# nrf7140_application register map
Vendor: Nordic Semiconductor; Series: nRF71; File version: 1
CPU: CM33 r0p4, little endian, MPU, FPU, 3 interrupt priority bits, 480 interrupts, 8 SAU regions
Registers are 32-bit, read-write, reset 0x0 unless marked. A register's access mark holds for its fields unless they carry their own. Offsets are from the block's base; [hi:lo] are bit positions; lines under a group give offsets from that group; {n}, {i} and the like mark numbered series; 'fields as' and 'values as' point back to an identical list.

## GLOBAL_FICR_NS — Factory Information Configuration Registers
Base 0x0FFFE000
0x00 SOCINFO group — Unspecified
  0x00 PARTNO ro reset 0xFFFFFFFF — Part number.
    [31:0] PART
  0x04 HWREVISION ro reset 0xFFFFFFFF — Hardware revision.
    [31:0] HWREVISION — Hardvare revision.
  0x08 PRODUCTIONREVISION ro reset 0xFFFFFFFF — Production reversion.
0x0C BLE group — Unspecified
  0x00 ADDRTYPE ro reset 0xFFFFFFFF — Device address type.
    [0] TYPE
      0=Public address; 1=Random address
  {0x4+4j} ADDR[{j}] (j=0..1) ro reset 0xFFFFFFFF — Description collection: 48 bit device address.
    [31:0] ADDR — Device address [n].
  {0xC+4j} ER[{j}] (j=0..3) ro reset 0xFFFFFFFF — Description collection: Encryption Root.
    [31:0] ER — Encryption root word [n].
  {0x1C+4j} IR[{j}] (j=0..3) ro reset 0xFFFFFFFF — Description collection: Identity Root.
    [31:0] IR — Identity root word [n].
0x40 NFC group — Unspecified
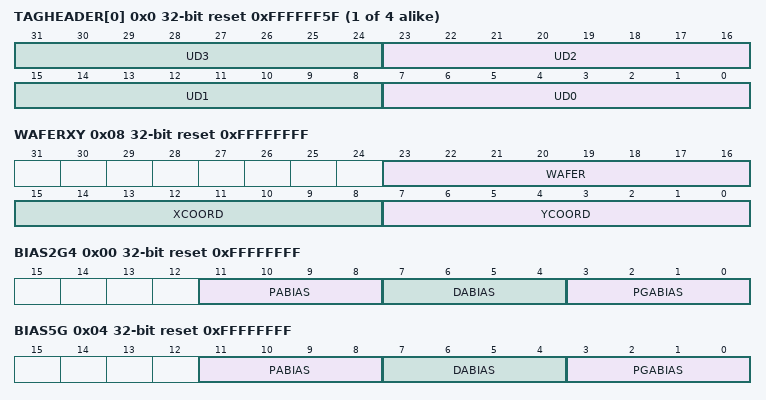
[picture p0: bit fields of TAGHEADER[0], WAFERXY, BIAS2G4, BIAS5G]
  {0x0+4j} TAGHEADER[{j}] (j=0..3) ro reset 0xFFFFFF5F — Description collection: Default header for NFC Tag.
    [8n+7:8n] UD{n} (n=0..3) — Unique identifier byte {n}
0x50 INFO group — Device info
  0x00 CONFIGID ro reset 0xFFFFFFFF — Configuration identifier
    [15:0] HWID — Identification number for the HW
  0x04 PART ro reset 0xFFFFFFFF — Part code
    [31:0] PART
      0xFFFFFFFF=Unspecified
  0x08 VARIANT ro reset 0xFFFFFFFF — Part Variant, Hardware version and Production configuration
    [31:0] VARIANT — Part Variant, Hardware version and Production configuration, encoded as ASCII
      0xFFFFFFFF=Unspecified
  0x0C PACKAGE ro reset 0xFFFFFFFF — Package option
    [31:0] PACKAGE
      0xFFFFFFFF=Unspecified
  0x10 RAM ro reset 0xFFFFFFFF — RAM variant
    [31:0] RAM
      0xFFFFFFFF=Unspecified
  0x14 MRAM ro reset 0xFFFFFFFF — MRAM variant
    [31:0] MRAM
      0xFFFFFFFF=Unspecified
  0x18 CODEPAGESIZE ro reset 0x1000 — Code memory page size in bytes
    [31:0] CODEPAGESIZE
      0xFFFFFFFF=Unspecified
  0x1C CODESIZE ro reset 0x100 — Code memory size
    [31:0] CODESIZE — Code memory size in number of pages
      0xFFFFFFFF=Unspecified
  0x20 DEVICETYPE ro
    [31:0] DEVICETYPE
      0=Die (Device is an physical DIE); 0xFFFFFFFF=FPGA (Device is an FPGA)
0x80 WIFI group — Unspecified
  0x00 DISABLE5GHZ ro reset 0xFFFFFFFF
    [31:0] VALUE — Disable 5GHz support. Firmware reads at start of day. Set to 0x50FA50FA to disable 5GHz operation.
  {0x4+4j} MACADDR0[{j}] (j=0..2) ro reset 0xFFFFFFFF — Description collection: Least significant 4 bytes of default MAC address for VIF[n].
    [31:0] MACADDRLO — MAC address for VIF[n] bytes 3:0.
  {0x10+4j} MACADDR1[{j}] (j=0..2) ro reset 0xFFFFFFFF — Description collection: Most significant 2 bytes of default MAC address for VIF[n].
    [15:0] MACADDRHI — MAC address for VIF[n] bytes 5:4.
0xC0 PRODTEST group — Unspecified
  0x00 CP group — Unspecified
    {0x0+4k} LOTNR[{k}] (k=0..1) ro reset 0xFFFFFFFF — Description collection: Lot number.
      [31:0] LOTNR — Lot number
    0x08 WAFERXY ro reset 0xFFFFFFFF — Wafer number and die X,Y coordinate.
      [23:16] WAFER — Wafer number
      [15:8] XCOORD — Die x coordinate
      [7:0] YCOORD — Die y coordinate
    0x0C PROGVERSION1 ro reset 0xFFFFFFFF — CP1 test program version.
      [31:0] VAL — CP1 test program version
    0x10 PROGVERSION2 ro reset 0xFFFFFFFF — CP2 test program version.
      [31:0] VAL — CP2 test program version
    0x14 PASSID1 ro reset 0xFFFFFFFF — CP1 pass ID.
      [31:0] VAL
    0x18 PASSID2 ro reset 0xFFFFFFFF — CP2 pass ID.
      [31:0] VAL
    0x1C TIMESTAMP1 ro reset 0xFFFFFFFF — Timestamp for when CP1 starts or ends (YYYYMMDDTHHMMSS)
      [31:0] VAL — CP1 timestamp
    0x20 TIMESTAMP2 ro reset 0xFFFFFFFF — Timestamp for when CP2 starts or ends (YYYYMMDDTHHMMSS)
      [31:0] VAL — CP2 timestamp
  0x24 FT group — Unspecified
    0x00 PROGVERSION1 ro reset 0xFFFFFFFF — FT1 test program version.
      [31:0] PROGVERSION1 — FT1 test program version
    0x04 PROGVERSION2 ro reset 0xFFFFFFFF — FT2/EQA test program version.
      [31:0] PROGVERSION2 — FT2/EQA test program version
    0x08 PASSID1 ro reset 0xFFFFFFFF — FT1 pass ID.
      [31:0] VAL
    0x0C PASSID2 ro reset 0xFFFFFFFF — FT2/EQA pass ID.
      [31:0] VAL
    0x10 TIMESTAMP1 ro reset 0xFFFFFFFF — Timestamp for when FT1 starts or ends (YYYYMMDDTHHMMSS)
      [31:0] VAL — FT1 timestamp
    0x14 TIMESTAMP2 ro reset 0xFFFFFFFF — Timestamp for when FT2/EQA starts or ends (YYYYMMDDTHHMMSS)
      [31:0] VAL — FT2/EQA timestamp
0x100 TRIM group — Unspecified
  0x00 SYSCTRL group — Unspecified
    0x00 FLL16M group — Unspecified
      0x00 CONFIG group — Unspecified
        0x00 CFGCKSW16M ro reset 0xFFFFFFFF — Config value for SYSCTRL.FLL16M.CONFIG.CFGCKSW16M
          [31:0] VALUE — Config value
      0x04 TRIM group — Unspecified
        0x00 RCOARSE ro reset 0xFFFFFFFF — Trim value for SYSCTRL.FLL16M.TRIM.RCOARSE
          [31:0] VALUE — Trim value
        0x04 RFINE ro reset 0xFFFFFFFF — Trim value for SYSCTRL.FLL16M.TRIM.RFINE
          [31:0] VALUE — Trim value
        0x08 VSUP ro reset 0xFFFFFFFF — Trim value for SYSCTRL.FLL16M.TRIM.VSUP
          [31:0] VALUE — Trim value
        0x0C CKSW16MTRIM ro reset 0xFFFFFFFF — Trim value for SYSCTRL.FLL16M.TRIM.CKSW16MTRIM
          [31:0] VALUE — Trim value
        0x10 TCOEF ro reset 0xFFFFFFFF — Trim value for SYSCTRL.FLL16M.TRIM.TCOEF
          [31:0] VALUE — Trim value
    0x18 LFRC group — Unspecified
      0x00 CAL group — Unspecified
        0x00 LFRCOSCTRIM ro reset 0xFFFFFFFF — Trim value for SYSCTRL.LFRC.CAL.LFRCOSCTRIM
          [31:0] VALUE — Trim value
    0x1C LFXO group — Unspecified
      0x00 TRIM group — Unspecified
        0x00 PDLOWERTHR ro reset 0xFFFFFFFF — Trim value for SYSCTRL.LFXO.TRIM.PDLOWERTHR
          [31:0] VALUE — Trim value
        0x04 PDUPPERTHR ro reset 0xFFFFFFFF — Trim value for SYSCTRL.LFXO.TRIM.PDUPPERTHR
          [31:0] VALUE — Trim value
        0x08 BIAS ro reset 0xFFFFFFFF — Trim value for SYSCTRL.LFXO.TRIM.BIAS
          [31:0] VALUE — Trim value
        0x0C PIXO ro reset 0xFFFFFFFF — Trim value for SYSCTRL.LFXO.TRIM.PIXO
          [31:0] VALUE — Trim value
        0x10 TRIMBUS ro reset 0xFFFFFFFF — Trim value for SYSCTRL.LFXO.TRIM.TRIMBUS
          [31:0] VALUE — Trim value
    0x30 HFXO64M group — Unspecified
      0x00 TRIM group — Unspecified
        0x00 DOUBLERCOMP ro reset 0xFFFFFFFF — Trim value for SYSCTRL.HFXO64M.TRIM.DOUBLERCOMP
          [31:0] VALUE — Trim value
        0x04 CHIRPTUNE ro reset 0xFFFFFFFF — Trim value for SYSCTRL.HFXO64M.TRIM.CHIRPTUNE
          [31:0] VALUE — Trim value
        0x08 RTUNE ro reset 0xFFFFFFFF — Trim value for SYSCTRL.HFXO64M.TRIM.RTUNE
          [31:0] VALUE — Trim value
    0x3C LFLPRC group — Unspecified
      0x00 VSUP ro reset 0xFFFFFFFF — Trim value for SYSCTRL.LFLPRC.TRIM.VSUP
        [31:0] VALUE — Trim value
      0x04 RCOARSE ro reset 0xFFFFFFFF — Trim value for SYSCTRL.LFLPRC.TRIM.RCOARSE
        [31:0] VALUE — Trim value
      0x08 RFINE ro reset 0xFFFFFFFF — Trim value for SYSCTRL.LFLPRC.TRIM.RFINE
        [31:0] VALUE — Trim value
      0x0C PWMFINE ro reset 0xFFFFFFFF — Trim value for SYSCTRL.LFLPRC.TRIM.PWMFINE
        [31:0] VALUE — Trim value
    0x4C VDETPOF5V0 group — Unspecified
      0x00 TRIM group — Unspecified
        0x00 POFWARN ro reset 0xFFFFFFFF — Trim value for SYSCTRL.VDETPOF5V0.TRIM.POFWARN
          [31:0] VALUE — Trim value
    0x50 VDETPOFVBAT group — Unspecified
      0x00 TRIM group — Unspecified
        0x00 POFWARN ro reset 0xFFFFFFFF — Trim value for SYSCTRL.VDETPOFVBAT.TRIM.POFWARN
          [31:0] VALUE — Trim value
    0x80 MBIAS group — Unspecified
      0x00 CONFIG group — Unspecified
        0x00 CFG ro reset 0xFFFFFFFF — Config value for SYSCTRL.MBIAS.CONFIG.CFG
          [31:0] VALUE — Trim value
      0x04 TRIM group — Unspecified
        0x00 MBIASIBPP ro reset 0xFFFFFFFF — Trim value for SYSCTRL.MBIAS.TRIM.MBIASIBPP
          [31:0] VALUE — Trim value
        0x04 MBIASIBPSR ro reset 0xFFFFFFFF — Trim value for SYSCTRL.MBIAS.TRIM.MBIASIBPSR
          [31:0] VALUE — Trim value
    0x8C OSCRFR group — Unspecified
      0x00 TRIM group — Unspecified
        0x00 OSC ro reset 0xFFFFFFFF — Trim value for SYSCTRL.OSCRFR.TRIM.OSC
          [31:0] VALUE — Trim value
        0x04 IBPSR ro reset 0xFFFFFFFF — Trim value for SYSCTRL.OSCRFR.TRIM.IBPSR
          [31:0] VALUE — Trim value
    0x94 VREG1V0 group — Unspecified
      0x00 TRIM group — Unspecified
        0x00 IREF ro reset 0xFFFFFFFF — Trim value for SYSCTRL.VREG1V0.TRIM.IREF
          [31:0] VALUE — Trim value
        0x04 HIGHPOWER ro reset 0xFFFFFFFF — Trim value for SYSCTRL.VREG1V0.TRIM.HIGHPOWER
          [31:0] VALUE — Trim value
        0x08 LOWPOWER ro reset 0xFFFFFFFF — Trim value for SYSCTRL.VREG1V0.TRIM.LOWPOWER
          [31:0] VALUE — Trim value
        0x0C ULPR ro reset 0xFFFFFFFF — Trim value for SYSCTRL.VREG1V0.TRIM.ULPR
          [31:0] VALUE — Trim value
      0x10 VOUTHPNOMINAL ro reset 0xFFFFFFFF — Config value for SYSCTRL.VREG1V0.VOUTHPNOMINAL
        [31:0] VALUE — Config value
    0xA8 VREGAO0V8 group — Unspecified
      0x00 TRIM group — Unspecified
        0x00 IREF ro reset 0xFFFFFFFF — Trim value for SYSCTRL.VREGAO0V8.TRIM.IREF
          [31:0] VALUE — Trim value
        0x04 HIGHPOWER ro reset 0xFFFFFFFF — Trim value for SYSCTRL.VREGAO0V8.TRIM.HIGHPOWER
          [31:0] VALUE — Trim value
        0x08 LOWPOWER ro reset 0xFFFFFFFF — Trim value for SYSCTRL.VREGAO0V8.TRIM.LOWPOWER
          [31:0] VALUE — Trim value
        0x0C ULTRALOWPOWER ro reset 0xFFFFFFFF — Trim value for SYSCTRL.VREGAO0V8.TRIM.ULTRALOWPOWER
          [31:0] VALUE — Trim value
        0x10 BPDET ro reset 0xFFFFFFFF — Trim value for SYSCTRL.VREGAO0V8.TRIM.BPDET
          [31:0] VALUE — Trim value
    0xBC VREGAO1V8 group — Unspecified
      0x00 TRIM group — Unspecified
        0x00 IREF ro reset 0xFFFFFFFF — Trim value for SYSCTRL.VREGAO1V8.TRIM.IREF
          [31:0] VALUE — Trim value
        0x04 VREF ro reset 0xFFFFFFFF — Trim value for SYSCTRL.VREGAO1V8.TRIM.VREF
          [31:0] VALUE — Trim value
        0x08 LOWPOWER ro reset 0xFFFFFFFF — Trim value for SYSCTRL.VREGAO1V8.TRIM.LOWPOWER
          [31:0] VALUE — Trim value
        0x0C LOWPOWERDIFF ro reset 0xFFFFFFFF — Trim value for SYSCTRL.VREGAO1V8.TRIM.LOWPOWERDIFF
          [31:0] VALUE — Trim value
    0xCC VREGMAIN group — Unspecified
      0x00 TRIM group — Unspecified
        0x00 BIASIBPP ro reset 0xFFFFFFFF — Trim value for SYSCTRL.VREGMAIN.TRIM.BIASIBPP
          [31:0] VALUE — Trim value
        0x04 BIASIBPSR ro reset 0xFFFFFFFF — Trim value for SYSCTRL.VREGMAIN.TRIM.BIASIBPSR
          [31:0] VALUE — Trim value
        0x08 VDDAO1V8HYSTOUTPUT ro reset 0xFFFFFFFF — Trim value for SYSCTRL.VREGMAIN.TRIM.VDDAO1V8HYSTOUTPUT
          [31:0] VALUE — Trim value
        0x0C VDDAO1V8PWMOUTPUT ro reset 0xFFFFFFFF — Trim value for SYSCTRL.VREGMAIN.TRIM.VDDAO1V8PWMOUTPUT
          [31:0] VALUE — Trim value
        0x10 VDD1V0HYSTOUTPUT ro reset 0xFFFFFFFF — Trim value for SYSCTRL.VREGMAIN.TRIM.VDD1V0HYSTOUTPUT
          [31:0] VALUE — Trim value
        0x14 VDDVS0V8HYSTOUTPUT ro reset 0xFFFFFFFF — Trim value for SYSCTRL.VREGMAIN.TRIM.VDDVS0V8HYSTOUTPUT
          [31:0] VALUE — Trim value
        0x18 VDDVS0V8PWMOUTPUT ro reset 0xFFFFFFFF — Trim value for SYSCTRL.VREGMAIN.TRIM.VDDVS0V8PWMOUTPUT
          [31:0] VALUE — Trim value
        0x1C VDD1V0PWMOUTPUT ro reset 0xFFFFFFFF — Trim value for SYSCTRL.VREGMAIN.TRIM.VDD1V0PWMOUTPUT
          [31:0] VALUE — Trim value
        0x20 ZCROSS ro reset 0xFFFFFFFF — Trim value for SYSCTRL.VREGMAIN.TRIM.ZCROSS
          [31:0] VALUE — Trim value
        0x24 HSILIM ro reset 0xFFFFFFFF — Trim value for SYSCTRL.VREGMAIN.TRIM.HSILIM
          [31:0] VALUE — Trim value
        0x28 ICMP ro reset 0xFFFFFFFF — Trim value for SYSCTRL.VREGMAIN.TRIM.ICMP
          [31:0] VALUE — Trim value
        0x2C VGND ro reset 0xFFFFFFFF — Trim value for SYSCTRL.VREGMAIN.TRIM.VGND
          [31:0] VALUE — Trim value
      0x30 CONFIG group — Unspecified
        0x00 CFGCH1 ro reset 0xFFFFFFFF — Config value for SYSCTRL.VREGMAIN.CONFIG.CFGCH1
          [31:0] VALUE — Config value
      0x34 MODE ro reset 0xFFFFFFFF — Config value for SYSCTRL.VREGMAIN.MODE
        [31:0] VALUE — Config value
    0x104 VREGMRAM130 group — Unspecified
      0x00 TRIM group — Unspecified
        0x00 VBG ro reset 0xFFFFFFFF — Trim value for SYSCTRL.VREGMRAM130.TRIM.VBG
          [31:0] VALUE — Trim value
        0x04 BIAS ro reset 0xFFFFFFFF — Trim value for SYSCTRL.VREGMRAM130.TRIM.BIAS
          [31:0] VALUE — Trim value
        0x08 VPR ro reset 0xFFFFFFFF — Trim value for SYSCTRL.VREGMRAM130.TRIM.VPR
          [31:0] VALUE — Trim value
        0x0C VREF ro reset 0xFFFFFFFF — Trim value for SYSCTRL.VREGMRAM130.TRIM.VREF
          [31:0] VALUE — Trim value
    0x114 VREGMRAM131 group — Unspecified
      0x00 TRIM group — Unspecified
        0x00 VBG ro reset 0xFFFFFFFF — Trim value for SYSCTRL.VREGMRAM131.TRIM.VBG
          [31:0] VALUE — Trim value
        0x04 BIAS ro reset 0xFFFFFFFF — Trim value for SYSCTRL.VREGMRAM131.TRIM.BIAS
          [31:0] VALUE — Trim value
        0x08 VPR ro reset 0xFFFFFFFF — Trim value for SYSCTRL.VREGMRAM131.TRIM.VPR
          [31:0] VALUE — Trim value
        0x0C VREF ro reset 0xFFFFFFFF — Trim value for SYSCTRL.VREGMRAM131.TRIM.VREF
          [31:0] VALUE — Trim value
    0x124 VREGVS0V8 group — Unspecified
      0x00 TRIM group — Unspecified
        0x00 IREF ro reset 0xFFFFFFFF — Trim value for SYSCTRL.VREGVS0V8.TRIM.IREF
          [31:0] VALUE — Trim value
        0x04 HIGHPOWER ro reset 0xFFFFFFFF — Trim value for SYSCTRL.VREGVS0V8.TRIM.HIGHPOWER
          [31:0] VALUE — Trim value
        0x08 LOWPOWER ro reset 0xFFFFFFFF — Trim value for SYSCTRL.VREGVS0V8.TRIM.LOWPOWER
          [31:0] VALUE — Trim value
        0x0C ULPR ro reset 0xFFFFFFFF — Trim value for SYSCTRL.VREGVS0V8.TRIM.ULPR
          [31:0] VALUE — Trim value
    0x134 VREGUSB group — Unspecified
      0x00 TRIM group — Unspecified
        0x00 TRIMVDD ro reset 0xFFFFFFFF — Trim value for SYSCTRL.VREGUSB.TRIM.TRIMVDD
          [31:0] VALUE — Trim value
        0x04 TRIMIBP ro reset 0xFFFFFFFF — Trim value for SYSCTRL.VREGUSB.TRIM.TRIMIBP
          [31:0] VALUE — Trim value
        0x08 TRIM0V8 ro reset 0xFFFFFFFF — Trim value for SYSCTRL.VREGUSB.TRIM.TRIM0V8
          [31:0] VALUE — Trim value
        0x0C TRIM3V3 ro reset 0xFFFFFFFF — Trim value for SYSCTRL.VREGUSB.TRIM.TRIM3V3
          [31:0] VALUE — Trim value
    0x144 VDETAO0V8 group — Unspecified
      0x00 TRIM group — Unspecified
        0x00 BROWNOUT ro reset 0xFFFFFFFF — Trim value for SYSCTRL.VDETAO0V8.TRIM.BROWNOUT
          [31:0] VALUE — Trim value
        0x04 PWRGOOD ro reset 0xFFFFFFFF — Trim value for SYSCTRL.VDETAO0V8.TRIM.PWRGOOD
          [31:0] VALUE — Trim value
      0x08 CONFIG group — Unspecified
        0x00 BROWNOUTHP ro reset 0xFFFFFFFF — Config value for SYSCTRL.VDETAO0V8.CONFIG.BROWNOUTHP
          [31:0] VALUE — Config value
    0x150 VDETAO1V8 group — Unspecified
      0x00 TRIM group — Unspecified
        0x00 BROWNOUTLVLHIGH ro reset 0xFFFFFFFF — Trim value for SYSCTRL.VDETAO1V8.TRIM.BROWNOUTLVLHIGH
          [31:0] VALUE — Trim value
        0x04 BROWNOUTLVLLOW ro reset 0xFFFFFFFF — Trim value for SYSCTRL.VDETAO1V8.TRIM.BROWNOUTLVLLOW
          [31:0] VALUE — Trim value
    0x158 VDETVS0V8 group — Unspecified
      0x00 TRIM group — Unspecified
        0x00 BROWNOUT ro reset 0xFFFFFFFF — Trim value for SYSCTRL.VDETVS0V8.TRIM.BROWNOUT
          [31:0] VALUE — Trim value
        0x04 PWRGOOD ro reset 0xFFFFFFFF — Trim value for SYSCTRL.VDETVS0V8.TRIM.PWRGOOD
          [31:0] VALUE — Trim value
    0x160 VDETAO5V0 group — Unspecified
      0x00 TRIM group — Unspecified
        0x00 PWRGOOD ro reset 0xFFFFFFFF — Trim value for SYSCTRL.VDETAO5V0.TRIM.PWRGOOD
          [31:0] VALUE — Trim value
    0x164 VDET1V0 group — Unspecified
      0x00 TRIM group — Unspecified
        0x00 PWRGOOD ro reset 0xFFFFFFFF — Trim value for SYSCTRL.VDET1V0.TRIM.PWRGOOD
          [31:0] VALUE — Trim value
    0x168 HSFLL120 group — Unspecified
      0x00 TRIM group — Unspecified
        0x00 VSUP ro reset 0xFFFFFFFF — Trim value for SYSCTRL.HSFLL120.TRIM.VSUP
          [31:0] VALUE — Trim value
        {0x4+4m} COARSE[{m}] (m=0..5) ro reset 0xFFFFFFFF — Description collection: Trim value for SYSCTRL.HSFLL120.TRIM.COARSE
          [31:0] VALUE — Trim value
        {0x1C+4m} FINE[{m}] (m=0..5) ro reset 0xFFFFFFFF — Description collection: Trim value for SYSCTRL.HSFLL120.TRIM.FINE
          [31:0] VALUE — Trim value
        0x34 TCOEF ro reset 0xFFFFFFFF — Trim value for SYSCTRL.HSFLL120.TRIM.TCOEF
          [31:0] VALUE — Trim value
    0x1A0 HSFLL121 group — Unspecified
      0x00 TRIM group — Unspecified
        0x00 VSUP ro reset 0xFFFFFFFF — Trim value for SYSCTRL.HSFLL121.TRIM.VSUP
          [31:0] VALUE — Trim value
        {0x4+4m} COARSE[{m}] (m=0..5) ro reset 0xFFFFFFFF — Description collection: Trim value for SYSCTRL.HSFLL121.TRIM.COARSE
          [31:0] VALUE — Trim value
        {0x1C+4m} FINE[{m}] (m=0..5) ro reset 0xFFFFFFFF — Description collection: Trim value for SYSCTRL.HSFLL121.TRIM.FINE
          [31:0] VALUE — Trim value
        0x34 TCOEF ro reset 0xFFFFFFFF — Trim value for SYSCTRL.HSFLL121.TRIM.TCOEF
          [31:0] VALUE — Trim value
    0x1D8 HSFLL122 group — Unspecified
      0x00 TRIM group — Unspecified
        0x00 VSUP ro reset 0xFFFFFFFF — Trim value for SYSCTRL.HSFLL122.TRIM.VSUP
          [31:0] VALUE — Trim value
        {0x4+4m} COARSE[{m}] (m=0..5) ro reset 0xFFFFFFFF — Description collection: Trim value for SYSCTRL.HSFLL122.TRIM.COARSE
          [31:0] VALUE — Trim value
        {0x1C+4m} FINE[{m}] (m=0..5) ro reset 0xFFFFFFFF — Description collection: Trim value for SYSCTRL.HSFLL122.TRIM.FINE
          [31:0] VALUE — Trim value
        0x34 TCOEF ro reset 0xFFFFFFFF — Trim value for SYSCTRL.HSFLL122.TRIM.TCOEF
          [31:0] VALUE — Trim value
    0x210 MEMCONF120 group — Unspecified
      {0x0+4l} REPAIR[{l}] (l=0..18) group — Unspecified
        0x00 BITLINE ro reset 0xFFFFFFFF — Description cluster: Trim value for SYSCTRL.MEMCONF120.REPAIR[n].BITLINE
          [31:0] VALUE — Trim value
      {0x4C+4l} BLOCKTYPE[{l}] (l=0..7) group — Unspecified
        0x00 TRIM ro reset 0xFFFFFFFF — Description cluster: Trim value for SYSCTRL.MEMCONF120.BLOCKTYPE[n].TRIM
          [31:0] VALUE — Trim value
    0x27C MEMCONF130 group — Unspecified
      {0x0+4l} BLOCKTYPE[{l}] (l=0..2) group — Unspecified
        0x00 TRIM ro reset 0xFFFFFFFF — Description cluster: Trim value for SYSCTRL.MEMCONF130.BLOCKTYPE[n].TRIM
          [31:0] VALUE — Trim value
  0x288 GLOBAL group — Unspecified
    0x00 SAADC group — Unspecified
      {0x0+4l} CAL[{l}] (l=0..2) ro reset 0xFFFFFFFF — Description collection: Trim value for GLOBAL.SAADC.CAL
        [31:0] VALUE — Trim value
      0x0C CALREF ro reset 0xFFFFFFFF — Trim value for GLOBAL.SAADC.CALREF
        [31:0] VALUE — Trim value
      {0x10+4l} LINCALCOEFF[{l}] (l=0..5) ro reset 0xFFFFFFFF — Description collection: Trim value for GLOBAL.SAADC.TRIM.LINCALCOEFF
        [31:0] VALUE — Trim value
    0x28 TEMP group — Unspecified
      0x00 CALIB ro reset 0xFFFFFFFF — Trim value for GLOBAL.TEMP.CALIB
        [31:0] VALUE — Trim value
    0x2C NFCT group — Unspecified
      0x00 BIASCFG ro reset 0xFFFFFFFF — Trim value for NFCT.BIASCFG
        [31:0] VALUE — Trim value
    0x30 CANPLL group — Unspecified
      0x00 TRIM group — Unspecified
        0x00 CTUNE ro reset 0xFFFFFFFF — Trim value for GLOBAL.CANPLL.TRIM.CTUNE
          [31:0] VALUE — Trim value
    0x34 CANPLLPM group — Unspecified
      0x00 TRIM group — Unspecified
        0x00 VREFPM ro reset 0xFFFFFFFF — Trim value for GLOBAL.CANPLLPM.TRIM.VREFPM
          [31:0] VALUE — Trim value
    0x38 COMP group — Unspecified
      0x00 REFTRIM ro reset 0xFFFFFFFF — Trim value for GLOBAL.COMP.REFTRIM
        [31:0] VALUE — Trim value
      0x04 RCALTRIM ro reset 0xFFFFFFFF — Trim value for GLOBAL.COMP.DFT.RCALTRIM
        [31:0] VALUE — Trim value
  0x2C8 APPLICATION group — Unspecified
    0x00 HSFLL group — Unspecified
      0x00 TRIM group — Unspecified
        0x00 VSUP ro reset 0xFFFFFFFF — Trim value for APPLICATION.HSFLL.TRIM.VSUP
          [31:0] VALUE — Trim value
        {0x4+4m} COARSE[{m}] (m=0..5) ro reset 0xFFFFFFFF — Description collection: Trim value for APPLICATION.HSFLL.TRIM.COARSE
          [31:0] VALUE — Trim value
        {0x1C+4m} FINE[{m}] (m=0..5) ro reset 0xFFFFFFFF — Description collection: Trim value for APPLICATION.HSFLL.TRIM.FINE
          [31:0] VALUE — Trim value
        0x34 TCOEF ro reset 0xFFFFFFFF — Trim value for APPLICATION.HSFLL.TRIM.TCOEF
          [31:0] VALUE — Trim value
    0x38 MEMCONF group — Unspecified
      {0x0+4l} BLOCKTYPE[{l}] (l=0..3) group — Unspecified
        0x00 TRIM ro reset 0xFFFFFFFF — Description cluster: Trim value for APPLICATION.MEMCONF.BLOCKTYPE[n].TRIM
          [31:0] VALUE — Trim value
  0x310 RADIOCORE group — Unspecified
    0x00 HSFLL group — Unspecified
      0x00 TRIM group — Unspecified
        0x00 VSUP ro reset 0xFFFFFFFF — Trim value for RADIOCORE.HSFLL.TRIM.VSUP
          [31:0] VALUE — Trim value
        {0x4+4m} COARSE[{m}] (m=0..5) ro reset 0xFFFFFFFF — Description collection: Trim value for RADIOCORE.HSFLL.TRIM.COARSE
          [31:0] VALUE — Trim value
        {0x1C+4m} FINE[{m}] (m=0..5) ro reset 0xFFFFFFFF — Description collection: Trim value for RADIOCORE.HSFLL.TRIM.FINE
          [31:0] VALUE — Trim value
        0x34 TCOEF ro reset 0xFFFFFFFF — Trim value for RADIOCORE.HSFLL.TRIM.TCOEF
          [31:0] VALUE — Trim value
    0x38 MEMCONF group — Unspecified
      {0x0+4l} BLOCKTYPE[{l}] (l=0..3) group — Unspecified
        0x00 TRIM ro reset 0xFFFFFFFF — Description cluster: Trim value for RADIOCORE.MEMCONF.BLOCKTYPE[n].TRIM
          [31:0] VALUE — Trim value
    0x48 RADIO group — Unspecified
      0x00 SPHYNXANA group — Unspecified
        {0x0+4m} FSCTRL{m} ro reset 0xFFFFFFFF (m=0..2) — Trim value for RADIOCORE.RADIO.SPHYNXANA.FSCTRL{m}
          [31:0] VALUE — Trim value
        0x0C RXCTRL ro reset 0xFFFFFFFF — Trim value for RADIOCORE.RADIO.SPHYNXANA.RXCTRL
          [31:0] VALUE — Trim value
        0x10 OVRRXTRIMCODE ro reset 0xFFFFFFFF — Trim value for RADIOCORE.RADIO.SPHYNXANA.OVRRXTRIMCODE
          [31:0] VALUE — Trim value
      0x14 RXAGC group — Unspecified
        0x00 CALIBRATION ro reset 0xFFFFFFFF — RADIOCORE.RADIO.RXAGC.CALIBRATION
          [31:0] VALUE — Trim value
      0x18 PVTTOT ro reset 0xFFFFFFFF — Trim value for RADIOCORE.RADIO.PVTTOT
        [31:0] VALUE — Trim value
      0x1C KDTC ro reset 0xFFFFFFFF — Trim value for RADIOCORE.RADIO.KDTC
        [31:0] VALUE — Trim value
      0x20 TXHFGAIN ro reset 0xFFFFFFFF — Trim value for RADIOCORE.RADIO.TXHFGAIN
        [31:0] VALUE — Trim value
      0x24 PVTTOFIX ro reset 0xFFFFFFFF — Trim value for RADIOCORE.RADIO.PVTTOFIX
        [31:0] VALUE — Trim value
      0x28 LOOPGAIN ro reset 0xFFFFFFFF — Trim value for RADIOCORE.RADIO.ADPLLTRIMCOMMAND0
        [31:0] VALUE — Trim value
  0x384 VREG1V80V8 group — Unspecified
    0x00 TRIM group — Unspecified
      0x00 IREF ro reset 0xFFFFFFFF — Trim value for SYSCTRL.VREGVS0V8.TRIM.IREF
        [31:0] VALUE — Trim value
      0x04 HIGHPOWER ro reset 0xFFFFFFFF — Trim value for SYSCTRL.VREGVS0V8.TRIM.HIGHPOWER
        [31:0] VALUE — Trim value
      0x08 LOWPOWER ro reset 0xFFFFFFFF — Trim value for SYSCTRL.VREGVS0V8.TRIM.LOWPOWER
        [31:0] VALUE — Trim value
      0x0C ULPR ro reset 0xFFFFFFFF — Trim value for SYSCTRL.VREGVS0V8.TRIM.ULPR
        [31:0] VALUE — Trim value
  0x394 AUDIOPLL group — Unspecified
    0x00 TRIM group — Unspecified
      0x00 CTUNE ro reset 0xFFFFFFFF — Trim value for SYSCTRL.AUDIOPLL.TRIM.CTUNE
        [31:0] VALUE — Trim value
  0x398 AUDIOPLLPM group — Unspecified
    0x00 TRIM group — Unspecified
      0x00 VREFPM ro reset 0xFFFFFFFF — Trim value for SYSCTRL.AUDIOPLLPM.TRIM.VREFPM
        [31:0] VALUE — Trim value
  0x39C USBHSPLL group — Unspecified
    0x00 TRIM group — Unspecified
      0x00 CTUNE ro reset 0xFFFFFFFF — Trim value for SYSCTRL.USBHSPLL.TRIM.CTUNE
        [31:0] VALUE — Trim value
  0x3CC BOOT group — Unspecified
    0x00 GPIO group — Unspecified
      0x00 PORTCNF group — Unspecified
        0x00 DRIVECTRL group — Unspecified
          {0x0+4p} P[{p}] (p=0..1) ro reset 0xFFFFFFFF — Description collection: Trim value for GPIO.Pn.PORTCNF.DRIVECTRL
            [31:0] VALUE — Trim value
    0x08 VREG1V0 group — Unspecified
      0x00 VOUTHPRADIOHELPER ro reset 0xFFFFFFFF — Config value for SYSCTRL.VREG1V0.VOUTHPRADIO when VREG1V0 used in Helper mode
        [31:0] VALUE — Config value
      0x04 VOUTHPNOMINAL ro reset 0xFFFFFFFF — Config value for SYSCTRL.VREG1V0.VOUTHPNOMINAL
        [31:0] VALUE — Config value
    0x10 HSFLL120 group — Unspecified
      0x00 TRIM group — Unspecified
        0x00 VSUP ro reset 0xFFFFFFFF — Trim value for SYSCTRL.HSFLL120.TRIM.VSUP
          [31:0] VALUE — Trim value
        0x04 COARSE ro reset 0xFFFFFFFF — Trim value for SYSCTRL.HSFLL120.TRIM.COARSE
          [31:0] VALUE — Trim value
        0x08 FINE ro reset 0xFFFFFFFF — Trim value for SYSCTRL.HSFLL120.TRIM.FINE
          [31:0] VALUE — Trim value
        0x0C TCOEF ro reset 0xFFFFFFFF — Trim value for SYSCTRL.HSFLL120.TRIM.TCOEF
          [31:0] VALUE — Trim value
    0x20 OTPC group — Unspecified
      0x00 WAITSTATES ro reset 0xFFFFFFFF — Config value for GLOBAL.OTPC.WAITSTATES
      0x04 FREQUENCY ro reset 0xFFFFFFFF — Config value for GLOBAL.OTPC.FREQUENCY
        [31:0] FREQUENCY — Frequency in MHz
  0x3F4 COMMON group — Unspecified
    0x00 FFFF ro reset 0xFFFFFFFF — Value to be written to multibit MIRROR register in MMIs (MIRROR=1)
      [31:0] FFFF — Mirror register value
    0x04 ZERO ro reset 0xFFFFFFFF — Value to be written to MIRROR register in MMIs (MIRROR=0)
      [31:0] ZERO — Mirror register value
    0x08 ONE ro reset 0xFFFFFFFF — Value to be written to MIRROR register in MMIs (MIRROR=1)
      [31:0] ONE — Mirror register value
  0x400 SECURE group — Unspecified
    0x00 HSFLL group — Unspecified
      0x00 TRIM group — Unspecified
        0x00 VSUP ro reset 0xFFFFFFFF — Trim value for SECURE.HSFLL.TRIM.VSUP
          [31:0] VALUE — Trim value
        {0x4+4m} COARSE[{m}] (m=0..5) ro reset 0xFFFFFFFF — Description collection: Trim value for SECURE.HSFLL.TRIM.COARSE
          [31:0] VALUE — Trim value
        {0x1C+4m} FINE[{m}] (m=0..5) ro reset 0xFFFFFFFF — Description collection: Trim value for SECURE.HSFLL.TRIM.FINE
          [31:0] VALUE — Trim value
    0x34 HSFLL200 group — Unspecified
      0x00 TRIM group — Unspecified
        0x00 VSUP ro reset 0xFFFFFFFF — Trim value for SECURE.HSFLL200.TRIM.VSUP
          [31:0] VALUE — Trim value
        {0x4+4m} COARSE[{m}] (m=0..3) ro reset 0xFFFFFFFF — Description collection: Trim value for SECURE.HSFLL200.TRIM.COARSE
          [31:0] VALUE — Trim value
        {0x14+4m} FINE[{m}] (m=0..3) ro reset 0xFFFFFFFF — Description collection: Trim value for SECURE.HSFLL200.TRIM.FINE
          [31:0] VALUE — Trim value
    0x58 MEMCONF group — Unspecified
      {0x0+4l} BLOCKTYPE[{l}] (l=0..7) group — Unspecified
        0x00 TRIM ro reset 0xFFFFFFFF — Description cluster: Trim value for SECURE.MEMCONF.BLOCKTYPE[n].TRIM
          [31:0] VALUE — Trim value
    0x78 MEMCONF200 group — Unspecified
      0x00 BLOCKTYPE group — Unspecified
        0x00 TRIM ro reset 0xFFFFFFFF — Trim value for SECURE.MEMCONF200.BLOCKTYPE.TRIM
          [31:0] VALUE — Trim value
    0x7C TCOEFS group — Unspecified
      0x00 TRIM group — Unspecified
        0x00 HSFLL ro reset 0xFFFFFFFF — Trim value for SECURE.HSFLL.TRIM.TCOEF
          [31:0] VALUE — Trim value
        0x04 HSFLL200 ro reset 0xFFFFFFFF — Trim value for SECURE.HSFLL200.TRIM.TCOEF
          [31:0] VALUE — Trim value
  0x500 WIFICORE group — Unspecified
    0x00 HSFLL group — Unspecified
      0x00 TRIM group — Unspecified
        0x00 VSUP ro reset 0xFFFFFFFF — Trim value for WIFICORE.HSFLL.TRIM.VSUP
          [31:0] VALUE — Trim value
        0x04 COARSE ro reset 0xFFFFFFFF — Trim value for WIFICORE.HSFLL.TRIM.COARSE
          [31:0] VALUE — Trim value
        0x08 FINE ro reset 0xFFFFFFFF — Trim value for WIFICORE.HSFLL.TRIM.FINE
          [31:0] VALUE — Trim value
        0x0C TCOEF ro reset 0xFFFFFFFF — Trim value for WIFICORE.HSFLL.TRIM.TCOEF
          [31:0] VALUE — Trim value
    0x10 MEMCONF group — Unspecified
      {0x0+4l} REPAIR[{l}] (l=0..21) group — Unspecified
        0x00 BITLINE ro reset 0xFFFFFFFF — Description cluster: Value for WIFICORE.MEMCONF.REPAIR[n].BITLINE
          [31:0] VALUE — Repair value
      {0x58+4l} BLOCKTYPE[{l}] (l=0..29) group — Unspecified
        0x00 TRIM ro reset 0xFFFFFFFF — Description cluster: Trim value for WIFICORE.MEMCONF.BLOCKTYPE[n].TRIM
          [31:0] VALUE — Trim value
    0xE0 RADIO group — Unspecified
      0x00 BIAS2G4 ro reset 0xFFFFFFFF — Bias trim values for 2.4GHz operation
        [11:8] PABIAS — Trim value PA bias generator
        [7:4] DABIAS — Trim value DA bias generator
        [3:0] PGABIAS — Trim value PGA bias generator
      0x04 BIAS5G ro reset 0xFFFFFFFF — Bias trim values for 5GHz operation
        fields as TRIM.WIFICORE.RADIO.BIAS2G4
      {0x8+4l} LNAGAINMAPPING[{l}] (l=0..7) ro reset 0xFFFFFFFF — Description collection: Mapping of LNA gain index to gain in dB
        [7:0] GAIN — Gain value in dB for LNA index n
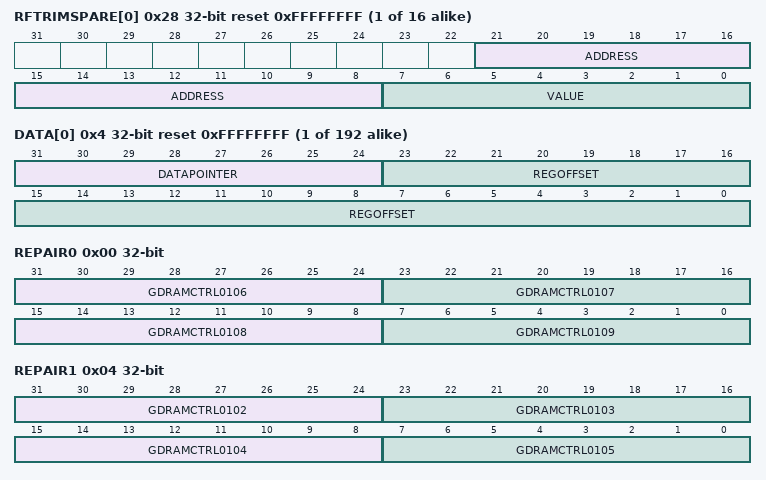
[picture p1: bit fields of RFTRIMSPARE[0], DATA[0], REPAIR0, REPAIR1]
      {0x28+4l} RFTRIMSPARE[{l}] (l=0..15) ro reset 0xFFFFFFFF — Description collection: Arbitrary RF register trim
        [21:8] ADDRESS — Register address to apply trim value to. Address 0x3FFF indicates unused trim value.
        [7:0] VALUE — Trim value to apply
  0x680 GRAPHICS group — Unspecified
    0x00 HSFLL group — Unspecified
      0x00 TRIM group — Unspecified
        0x00 VSUP ro reset 0xFFFFFFFF — Trim value for GRAPHICS.HSFLL.TRIM.VSUP
          [31:0] VALUE — Trim value
        0x04 COARSE ro reset 0xFFFFFFFF — Trim value for GRAPHICS.HSFLL.TRIM.COARSE
          [31:0] VALUE — Trim value
        0x08 FINE ro reset 0xFFFFFFFF — Trim value for GRAPHICS.HSFLL.TRIM.FINE
          [31:0] VALUE — Trim value
        0x0C TCOEF ro reset 0xFFFFFFFF — Trim value for GRAPHICS.HSFLL.TRIM.TCOEF
          [31:0] VALUE — Trim value
    0x10 MEMCONF group — Unspecified
      {0x0+4l} BLOCKTYPE[{l}] (l=0..11) group — Unspecified
        0x00 TRIM ro reset 0xFFFFFFFF — Description cluster: Trim value for GRAPHICS.MEMCONF.BLOCKTYPE[n].TRIM
          [31:0] VALUE — Trim value
    0x40 AUXPLL group — Unspecified
      0x00 TRIM group — Unspecified
        0x00 CTUNE ro reset 0xFFFFFFFF — Trim value for GRAPHICS.AUXPLL.CTUNE
          [31:0] VALUE — Trim value
    0x44 VREGGFX group — Unspecified
      0x00 TRIM group — Unspecified
        0x00 IREF ro reset 0xFFFFFFFF — Trim value for GRAPHICS.VREGGFX.IREF
          [31:0] VALUE — Trim value
        0x04 HIGHPOWER ro reset 0xFFFFFFFF — Trim value for GRAPHICS.VREGGFX.HIGHPOWER
          [31:0] VALUE — Trim value
        0x08 LOWPOWER ro reset 0xFFFFFFFF — Trim value for GRAPHICS.VREGGFX.LOWPOWER
          [31:0] VALUE — Trim value
        0x0C ULPR ro reset 0xFFFFFFFF — Trim value for GRAPHICS.VREGGFX.ULPR
          [31:0] VALUE — Trim value
  0x6E0 ML group — Unspecified
    0x00 HSFLL group — Unspecified
      0x00 TRIM group — Unspecified
        0x00 VSUP ro reset 0xFFFFFFFF — Trim value for ML.HSFLL.TRIM.VSUP
          [31:0] VALUE — Trim value
        {0x4+4m} COARSE[{m}] (m=0..5) ro reset 0xFFFFFFFF — Description collection: Trim value for ML.HSFLL.TRIM.COARSE
          [31:0] VALUE — Trim value
        {0x1C+4m} FINE[{m}] (m=0..5) ro reset 0xFFFFFFFF — Description collection: Trim value for ML.HSFLL.TRIM.FINE
          [31:0] VALUE — Trim value
        0x34 TCOEF ro reset 0xFFFFFFFF — Trim value for ML.HSFLL.TRIM.TCOEF
          [31:0] VALUE — Trim value
    0x38 MEMCONF group — Unspecified
      {0x0+4l} BLOCKTYPE[{l}] (l=0..2) group — Unspecified
        0x00 TRIM ro reset 0xFFFFFFFF — Description cluster: Trim value for ML.MEMCONF.BLOCKTYPE[n].TRIM
          [31:0] VALUE — Trim value
0x8A0 BOOT group — Unspecified
  0x00 SIZE ro reset 0xFFFFFFFF — Size of DATA group
    [31:0] VALUE — Number of trim values stored in DATA.
  {0x4+4j} DATA[{j}] (j=0..191) ro reset 0xFFFFFFFF — Description collection: Compressed address and data pointer.
    [31:24] DATAPOINTER — Pointer to location in TRIM group
    [23:0] REGOFFSET — Address offset to trim register
0xBB0 SRAM group — Unspecified
  0x00 REPAIR0 — SRAM repair register 0
    [879-8n:872-8n] GDRAMCTRL{n:04} (n=106..109) — GD RamController01 Ram {n-100}
  0x04 REPAIR1 — SRAM repair register 1
    [847-8n:840-8n] GDRAMCTRL{n:04} (n=102..105) — GD RamController01 Ram {n-100}
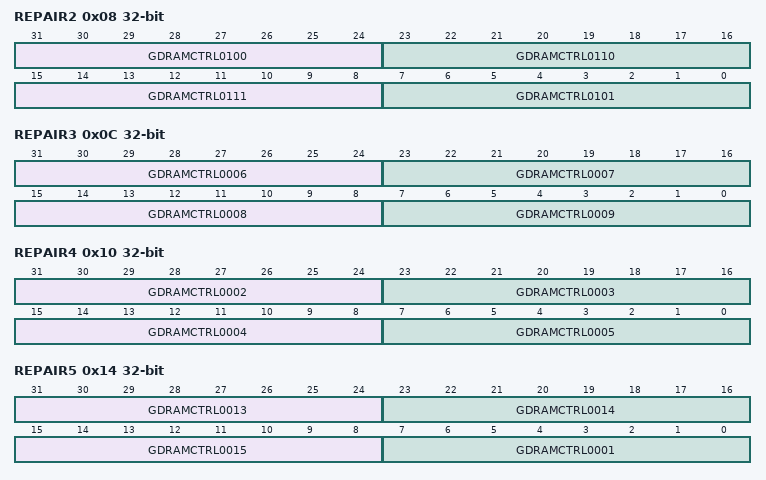
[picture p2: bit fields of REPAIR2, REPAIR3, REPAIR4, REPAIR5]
  0x08 REPAIR2 — SRAM repair register 2
    [31:24] GDRAMCTRL0100 — GD RamController01 Ram 0
    [23:16] GDRAMCTRL0110 — GD RamController01 Ram 10
    [15:8] GDRAMCTRL0111 — GD RamController01 Ram 11
    [7:0] GDRAMCTRL0101 — GD RamController01 Ram 1
  0x0C REPAIR3 — SRAM repair register 3
    [79-8n:72-8n] GDRAMCTRL{n:04} (n=6..9) — GD RamController00 Ram {n}
  0x10 REPAIR4 — SRAM repair register 4
    [47-8n:40-8n] GDRAMCTRL{n:04} (n=2..5) — GD RamController00 Ram {n}
  0x14 REPAIR5 — SRAM repair register 5
    [31:24] GDRAMCTRL0013 — GD RamController00 Ram 13
    [23:16] GDRAMCTRL0014 — GD RamController00 Ram 14
    [15:8] GDRAMCTRL0015 — GD RamController00 Ram 15
    [7:0] GDRAMCTRL0001 — GD RamController00 Ram 1
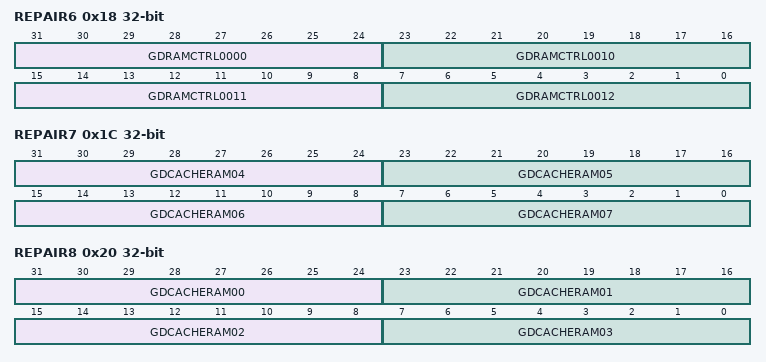
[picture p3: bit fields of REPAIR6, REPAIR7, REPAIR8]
  0x18 REPAIR6 — SRAM repair register 6
    [31:24] GDRAMCTRL0000 — GD RamController00 Ram 0
    [23:16] GDRAMCTRL0010 — GD RamController00 Ram 10
    [15:8] GDRAMCTRL0011 — GD RamController00 Ram 11
    [7:0] GDRAMCTRL0012 — GD RamController00 Ram 12
  0x1C REPAIR7 — SRAM repair register 7
    [63-8n:56-8n] GDCACHERAM{n:02} (n=4..7) — GD Cache Data Ram {n}
  0x20 REPAIR8 — SRAM repair register 8
    [31-8n:24-8n] GDCACHERAM{n:02} (n=0..3) — GD Cache Data Ram {n}
0xBFC CRC32 — CRC32 value for FICR (except this word)
  [31:0] VALUE — CRC32 value

## Notices in the file
Copyright (c) 2010 - 2024, Nordic Semiconductor ASA
All rights reserved.
Redistribution and use in source and binary forms, with or without modification,
are permitted provided that the following conditions are met:
1. Redistributions of source code must retain the above copyright notice, this
list of conditions and the following disclaimer.
2. Redistributions in binary form, except as embedded into a Nordic
Semiconductor ASA integrated circuit in a product or a software update for
such product, must reproduce the above copyright notice, this list of
conditions and the following disclaimer in the documentation and/or other
materials provided with the distribution.
3. Neither the name of Nordic Semiconductor ASA nor the names of its
contributors may be used to endorse or promote products derived from this
software without specific prior written permission.
4. This software, with or without modification, must only be used with a
Nordic Semiconductor ASA integrated circuit.
5. Any software provided in binary form under this license must not be reverse
engineered, decompiled, modified and/or disassembled.
THIS SOFTWARE IS PROVIDED BY NORDIC SEMICONDUCTOR ASA "AS IS" AND ANY EXPRESS
OR IMPLIED WARRANTIES, INCLUDING, BUT NOT LIMITED TO, THE IMPLIED WARRANTIES
OF MERCHANTABILITY, NONINFRINGEMENT, AND FITNESS FOR A PARTICULAR PURPOSE ARE
DISCLAIMED. IN NO EVENT SHALL NORDIC SEMICONDUCTOR ASA OR CONTRIBUTORS BE
LIABLE FOR ANY DIRECT, INDIRECT, INCIDENTAL, SPECIAL, EXEMPLARY, OR
CONSEQUENTIAL DAMAGES (INCLUDING, BUT NOT LIMITED TO, PROCUREMENT OF SUBSTITUTE
GOODS OR SERVICES; LOSS OF USE, DATA, OR PROFITS; OR BUSINESS INTERRUPTION)
HOWEVER CAUSED AND ON ANY THEORY OF LIABILITY, WHETHER IN CONTRACT, STRICT
LIABILITY, OR TORT (INCLUDING NEGLIGENCE OR OTHERWISE) ARISING IN ANY WAY OUT
OF THE USE OF THIS SOFTWARE, EVEN IF ADVISED OF THE POSSIBILITY OF SUCH DAMAGE.
